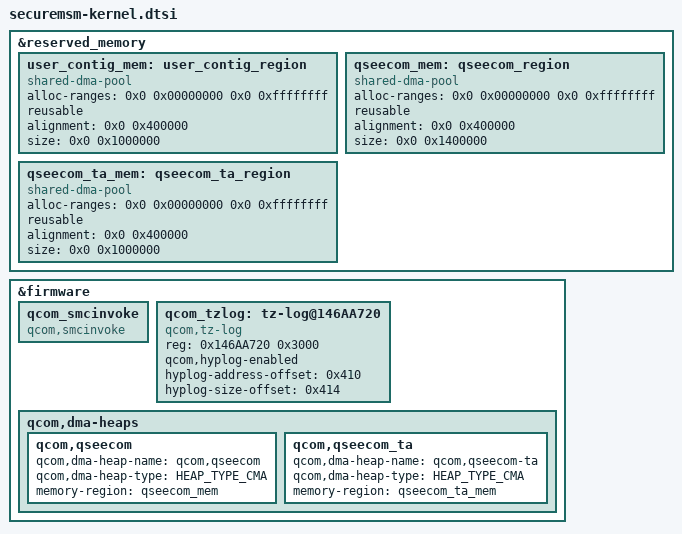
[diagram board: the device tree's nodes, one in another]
/dts-v1/;
/plugin/;

#include <dt-bindings/clock/qcom,aop-qmp.h>
#include <dt-bindings/interrupt-controller/arm-gic.h>
#include <dt-bindings/interconnect/qcom,icc.h>
#include <dt-bindings/regulator/qcom,rpmh-regulator-levels.h>
#include <dt-bindings/interconnect/qcom,waipio.h>
#include <dt-bindings/soc/qcom,ipcc.h>
#include <dt-bindings/soc/qcom,rpmh-rsc.h>
#include <dt-bindings/soc/qcom,ipcc.h>
#include <dt-bindings/spmi/spmi.h>
#include <dt-bindings/gpio/gpio.h>
#include <dt-bindings/power/qcom-aoss-qmp.h>

&reserved_memory {

    user_contig_mem: user_contig_region {
 		compatible = "shared-dma-pool";
 		alloc-ranges = <0x0 0x00000000 0x0 0xffffffff>;
 		reusable;
 		alignment = <0x0 0x400000>;
 		size = <0x0 0x1000000>;
 	};
	qseecom_mem: qseecom_region {
		compatible = "shared-dma-pool";
		alloc-ranges = <0x0 0x00000000 0x0 0xffffffff>;
		reusable;
		alignment = <0x0 0x400000>;
		size = <0x0 0x1400000>;
    };

 	qseecom_ta_mem: qseecom_ta_region {
 		compatible = "shared-dma-pool";
 		alloc-ranges = <0x0 0x00000000 0x0 0xffffffff>;
 		reusable;
 		alignment = <0x0 0x400000>;
 		size = <0x0 0x1000000>;
 	};
};
&firmware {
	qcom_smcinvoke {
 		compatible = "qcom,smcinvoke";
	};

	qcom_tzlog: tz-log@146AA720 {

		compatible = "qcom,tz-log";
		reg = <0x146AA720 0x3000>;
		qcom,hyplog-enabled;
		hyplog-address-offset = <0x410>;
		hyplog-size-offset = <0x414>;
	};

	qcom,dma-heaps {
		qcom,qseecom {
 			qcom,dma-heap-name = "qcom,qseecom";
 			qcom,dma-heap-type = <HEAP_TYPE_CMA>;
 			memory-region = <&qseecom_mem>;
 		};

 		qcom,qseecom_ta {
 			qcom,dma-heap-name = "qcom,qseecom-ta";
 			qcom,dma-heap-type = <HEAP_TYPE_CMA>;
 			memory-region = <&qseecom_ta_mem>;
 		};
	};
};




